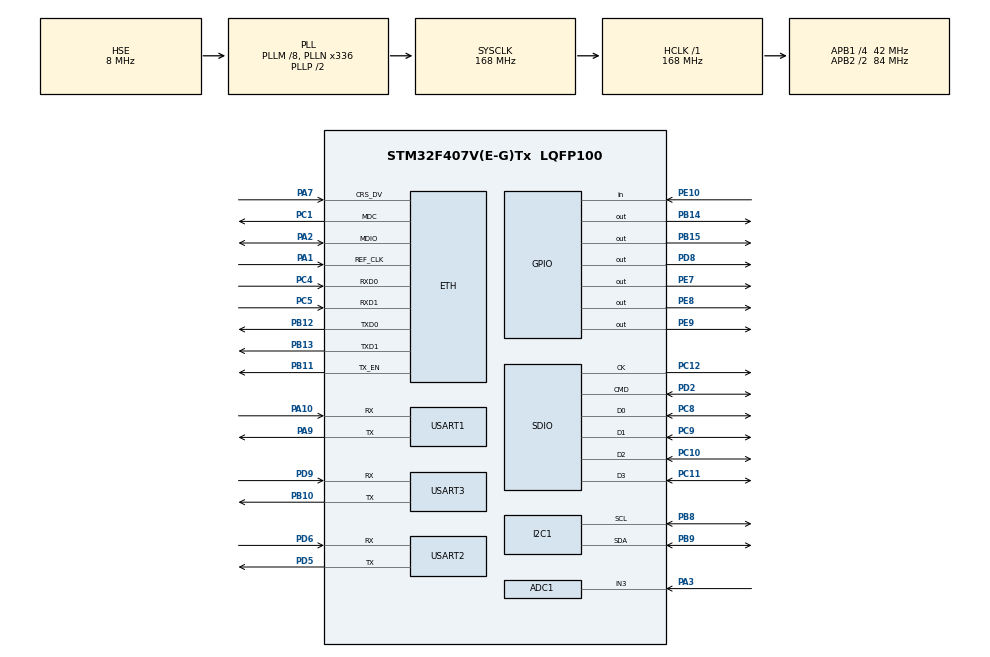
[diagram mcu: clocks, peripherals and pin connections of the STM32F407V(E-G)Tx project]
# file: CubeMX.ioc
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ADC1.Channel-0\#ChannelRegularConversion=ADC_CHANNEL_3
ADC1.NbrOfConversionFlag=1
ADC1.Rank-0\#ChannelRegularConversion=1
ADC1.SamplingTime-0\#ChannelRegularConversion=ADC_SAMPLETIME_3CYCLES
ADC1.master=1
ETH.MediaInterface=ETH_MEDIA_INTERFACE_RMII
FREERTOS.HEAP_NUMBER=3
FREERTOS.INCLUDE_eTaskGetState=0
FREERTOS.INCLUDE_pcTaskGetTaskName=1
FREERTOS.INCLUDE_vTaskDelayUntil=1
FREERTOS.INCLUDE_xQueueGetMutexHolder=0
FREERTOS.INCLUDE_xSemaphoreGetMutexHolder=0
FREERTOS.INCLUDE_xTaskGetCurrentTaskHandle=0
FREERTOS.Tasks01=defaultTask,0,128,StartDefaultTask,Default;keyboardTask,0,128,StartKeyboardTask,As external;ledIndicatorTask,0,128,StartLedIndicatorTask,As external;uartDebugTask,0,128,StartUartDebugTask,As external;HttpServerTask,0,128,StartHttpServerTask,As external;sdWorkerTask,0,128,StartSdWorkerTask,As external
FREERTOS.configCHECK_FOR_STACK_OVERFLOW=2
FREERTOS.configENABLE_BACKWARD_COMPATIBILITY=1
FREERTOS.configGENERATE_RUN_TIME_STATS=0
FREERTOS.configLIBRARY_LOWEST_INTERRUPT_PRIORITY=15
FREERTOS.configLIBRARY_MAX_SYSCALL_INTERRUPT_PRIORITY=5
FREERTOS.configMAX_PRIORITIES=16
FREERTOS.configMAX_TASK_NAME_LEN=24
FREERTOS.configTOTAL_HEAP_SIZE=15360
FREERTOS.configUSE_APPLICATION_TASK_TAG=0
FREERTOS.configUSE_COUNTING_SEMAPHORES=0
FREERTOS.configUSE_CO_ROUTINES=0
FREERTOS.configUSE_IDLE_HOOK=0
FREERTOS.configUSE_MALLOC_FAILED_HOOK=0
FREERTOS.configUSE_PORT_OPTIMISED_TASK_SELECTION=0
FREERTOS.configUSE_PREEMPTION=1
FREERTOS.configUSE_TICK_HOOK=0
FREERTOS.configUSE_TIMERS=0
LWIP.ARP_QUEUEING=0
LWIP.AUTOIP_DEBUG=LWIP_DBG_OFF
LWIP.CHECKSUM_BY_HARDWARE=0
LWIP.DEFAULT_THREAD_PRIO=7
LWIP.DHCP_DEBUG=LWIP_DBG_OFF
LWIP.DNS_DOES_NAME_CHECK=0
LWIP.ETHARP_SUPPORT_STATIC_ENTRIES=0
LWIP.ETHARP_SUPPORT_VLAN=0
LWIP.ETHARP_TABLE_MATCH_NETIF=0
LWIP.ETHARP_TRUST_IP_MAC=0
LWIP.GATEWAY_ADDRESS=192.168.001.001
LWIP.IP_ADDRESS=192.168.001.004
LWIP.IP_DEBUG=LWIP_DBG_OFF
LWIP.LWIP_DBG_TYPES_ON=LWIP_DBG_OFF
LWIP.LWIP_DHCP=1
LWIP.LWIP_DHCP_CHECK_LINK_UP=0
LWIP.LWIP_HAVE_SLIPIF=0
LWIP.LWIP_HTTPD=0
LWIP.LWIP_NETBUF_RECVINFO=1
LWIP.LWIP_NETCONN=1
LWIP.LWIP_NETCONN_SEM_PER_THREAD=0
LWIP.LWIP_NETIF_API=0
LWIP.LWIP_NETIF_HOSTNAME=0
LWIP.LWIP_NETIF_HWADDRHINT=0
LWIP.LWIP_NETIF_LINK_CALLBACK=0
LWIP.LWIP_NETIF_LOOPBACK=0
LWIP.LWIP_NETIF_REMOVE_CALLBACK=0
LWIP.LWIP_NETIF_STATUS_CALLBACK=0
LWIP.LWIP_SOCKET=1
LWIP.LWIP_SO_LINGER=0
LWIP.LWIP_SO_RCVBUF=0
LWIP.LWIP_STATS=0
LWIP.LWIP_TCP=1
LWIP.LWIP_TCPIP_TIMEOUT=0
LWIP.LWIP_TCP_TIMESTAMPS=1
LWIP.LWIP_UDP=1
LWIP.LWIP_UDPLITE=0
LWIP.MEMP_MEM_MALLOC=0
LWIP.MEM_LIBC_MALLOC=0
LWIP.NETIF_DEBUG=LWIP_DBG_OFF
LWIP.NETMASK_ADDRESS=255.255.255.000
LWIP.SOCKETS_DEBUG=LWIP_DBG_OFF
LWIP.SYS_LIGHTWEIGHT_PROT=0
LWIP.TCPIP_THREAD_PRIO=7
LWIP.UDP_DEBUG=LWIP_DBG_OFF
LWIP.Version=v1.5.0_RC0_20160211_Cube
Mcu.Family=STM32F4
Mcu.Name=STM32F407V(E-G)Tx
Mcu.Package=LQFP100
Mcu.UserConstants=configUSE_STATS_FORMATTING_FUNCTIONS,1
NVIC.ETH_IRQn=true\:5\:0\:true\:false\:true\:true
NVIC.PriorityGroup=NVIC_PRIORITYGROUP_4
PA1.Mode=RMII
PA1.Signal=ETH_REF_CLK
PA10.Mode=Asynchronous
PA10.Signal=USART1_RX
PA13.Mode=Serial_Wire
PA13.Signal=SYS_JTMS-SWDIO
PA14.Mode=Serial_Wire
PA14.Signal=SYS_JTCK-SWCLK
PA2.Mode=RMII
PA2.Signal=ETH_MDIO
PA3.Signal=ADCx_IN3
PA7.Mode=RMII
PA7.Signal=ETH_CRS_DV
PA9.Mode=Asynchronous
PA9.Signal=USART1_TX
PB10.Mode=Asynchronous
PB10.Signal=USART3_TX
PB11.Mode=RMII
PB11.Signal=ETH_TX_EN
PB12.Mode=RMII
PB12.Signal=ETH_TXD0
PB13.Mode=RMII
PB13.Signal=ETH_TXD1
PB14.Signal=GPIO_Output
PB15.Signal=GPIO_Output
PB8.Mode=I2C
PB8.Signal=I2C1_SCL
PB9.Mode=I2C
PB9.Signal=I2C1_SDA
PC1.Mode=RMII
PC1.Signal=ETH_MDC
PC10.Mode=SD_4_bits_Wide_bus
PC10.Signal=SDIO_D2
PC11.Mode=SD_4_bits_Wide_bus
PC11.Signal=SDIO_D3
PC12.Mode=SD_4_bits_Wide_bus
PC12.Signal=SDIO_CK
PC14-OSC32_IN.Mode=LSE-External-Oscillator
PC14-OSC32_IN.Signal=RCC_OSC32_IN
PC15-OSC32_OUT.Mode=LSE-External-Oscillator
PC15-OSC32_OUT.Signal=RCC_OSC32_OUT
PC4.Mode=RMII
PC4.Signal=ETH_RXD0
PC5.Mode=RMII
PC5.Signal=ETH_RXD1
PC8.Mode=SD_4_bits_Wide_bus
PC8.Signal=SDIO_D0
PC9.Mode=SD_4_bits_Wide_bus
PC9.Signal=SDIO_D1
PD2.Mode=SD_4_bits_Wide_bus
PD2.Signal=SDIO_CMD
PD5.Mode=Asynchronous
PD5.Signal=USART2_TX
PD6.Mode=Asynchronous
PD6.Signal=USART2_RX
PD8.Signal=GPIO_Output
PD9.Mode=Asynchronous
PD9.Signal=USART3_RX
PE10.Signal=GPIO_Input
PE7.Signal=GPIO_Output
PE8.Signal=GPIO_Output
PE9.Signal=GPIO_Output
PH0-OSC_IN.Mode=HSE-External-Oscillator
PH0-OSC_IN.Signal=RCC_OSC_IN
PH1-OSC_OUT.Mode=HSE-External-Oscillator
PH1-OSC_OUT.Signal=RCC_OSC_OUT
ProjectManager.HeapSize=0x200
ProjectManager.StackSize=0x400
ProjectManager.TargetToolchain=TrueSTUDIO
RCC.48MHZClocksFreq_Value=48000000
RCC.AHBFreq_Value=168000000
RCC.APB1CLKDivider=RCC_HCLK_DIV4
RCC.APB1Freq_Value=42000000
RCC.APB1TimFreq_Value=84000000
RCC.APB2CLKDivider=RCC_HCLK_DIV2
RCC.APB2Freq_Value=84000000
RCC.APB2TimFreq_Value=168000000
RCC.CortexFreq_Value=168000000
RCC.HCLKFreq_Value=168000000
RCC.HSE_VALUE=8000000
RCC.HSI_VALUE=16000000
RCC.PLLM=8
RCC.PLLN=336
RCC.PLLQ=7
RCC.PLLSourceVirtual=RCC_PLLSOURCE_HSE
RCC.SYSCLKFreq_VALUE=168000000
RCC.SYSCLKSource=RCC_SYSCLKSOURCE_PLLCLK
RCC.VCOOutputFreq_Value=336000000
SDIO.BusWide=SDIO_BUS_WIDE_1B
SDIO.WideMode=SDIO_BUS_WIDE_4B
SH.ADCx_IN3.0=ADC1_IN3,IN3
VP_ADC1_TempSens_Input.Mode=IN-TempSens
VP_ADC1_Vbat_Input.Mode=IN-Vbat
VP_ADC1_Vref_Input.Mode=IN-Vrefint
VP_FATFS_VS_Generic.Mode=User_defined
VP_FATFS_VS_SDIO.Mode=SDIO
VP_FREERTOS_VS_ENABLE.Mode=Enabled
VP_LWIP_VS_Enabled.Mode=Enabled
VP_TIM6_VS_ClockSourceINT.Mode=Enable_Timer
board=CubeMX

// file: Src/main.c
/**
  ******************************************************************************
  * File Name          : main.c
  * Description        : Main program body
  ******************************************************************************
  *
  * COPYRIGHT(c) 2016 STMicroelectronics
  *
  * Redistribution and use in source and binary forms, with or without modification,
  * are permitted provided that the following conditions are met:
  *   1. Redistributions of source code must retain the above copyright notice,
  *      this list of conditions and the following disclaimer.
  *   2. Redistributions in binary form must reproduce the above copyright notice,
  *      this list of conditions and the following disclaimer in the documentation
  *      and/or other materials provided with the distribution.
  *   3. Neither the name of STMicroelectronics nor the names of its contributors
  *      may be used to endorse or promote products derived from this software
  *      without specific prior written permission.
  *
  * THIS SOFTWARE IS PROVIDED BY THE COPYRIGHT HOLDERS AND CONTRIBUTORS "AS IS"
  * AND ANY EXPRESS OR IMPLIED WARRANTIES, INCLUDING, BUT NOT LIMITED TO, THE
  * IMPLIED WARRANTIES OF MERCHANTABILITY AND FITNESS FOR A PARTICULAR PURPOSE ARE
  * DISCLAIMED. IN NO EVENT SHALL THE COPYRIGHT HOLDER OR CONTRIBUTORS BE LIABLE
  * FOR ANY DIRECT, INDIRECT, INCIDENTAL, SPECIAL, EXEMPLARY, OR CONSEQUENTIAL
  * DAMAGES (INCLUDING, BUT NOT LIMITED TO, PROCUREMENT OF SUBSTITUTE GOODS OR
  * SERVICES; LOSS OF USE, DATA, OR PROFITS; OR BUSINESS INTERRUPTION) HOWEVER
  * CAUSED AND ON ANY THEORY OF LIABILITY, WHETHER IN CONTRACT, STRICT LIABILITY,
  * OR TORT (INCLUDING NEGLIGENCE OR OTHERWISE) ARISING IN ANY WAY OUT OF THE USE
  * OF THIS SOFTWARE, EVEN IF ADVISED OF THE POSSIBILITY OF SUCH DAMAGE.
  *
  ******************************************************************************
  */
#include "stm32f4xx_hal.h"
#include "cmsis_os.h"
#include "adc.h"
#include "fatfs.h"
#include "i2c.h"
#include "lwip.h"
#include "sdio.h"
#include "tim.h"
#include "usart.h"
#include "gpio.h"

/* USER CODE BEGIN PV */
/* Private variables ---------------------------------------------------------*/

/* USER CODE END PV */

void SystemClock_Config(void);
void Error_Handler(void);
void MX_FREERTOS_Init(void);

/* USER CODE BEGIN PFP */
/* Private function prototypes -----------------------------------------------*/

/* USER CODE END PFP */

int main(void)
{

  /* MCU Configuration----------------------------------------------------------*/

  /* Reset of all peripherals, Initializes the Flash interface and the Systick. */
  HAL_Init();

  /* Configure the system clock */
  SystemClock_Config();

  /* Initialize all configured peripherals */
  MX_GPIO_Init();
  MX_ADC1_Init();
  MX_I2C1_Init();
  MX_SDIO_SD_Init();
  MX_TIM6_Init();
  MX_USART3_UART_Init();
  MX_USART2_UART_Init();
  MX_USART1_UART_Init();

  /* Call init function for freertos objects (in freertos.c) */
  MX_FREERTOS_Init();

  /* Start scheduler */
  osKernelStart();

  /* We should never get here as control is now taken by the scheduler */

  /* Infinite loop */
  while (1)
  {

  }

}

/** System Clock Configuration
*/
void SystemClock_Config(void)
{

  RCC_OscInitTypeDef RCC_OscInitStruct;
  RCC_ClkInitTypeDef RCC_ClkInitStruct;

  __HAL_RCC_PWR_CLK_ENABLE();

  __HAL_PWR_VOLTAGESCALING_CONFIG(PWR_REGULATOR_VOLTAGE_SCALE1);

  RCC_OscInitStruct.OscillatorType = RCC_OSCILLATORTYPE_HSE;
  RCC_OscInitStruct.HSEState = RCC_HSE_ON;
  RCC_OscInitStruct.PLL.PLLState = RCC_PLL_ON;
  RCC_OscInitStruct.PLL.PLLSource = RCC_PLLSOURCE_HSE;
  RCC_OscInitStruct.PLL.PLLM = 8;
  RCC_OscInitStruct.PLL.PLLN = 336;
  RCC_OscInitStruct.PLL.PLLP = RCC_PLLP_DIV2;
  RCC_OscInitStruct.PLL.PLLQ = 7;
  if (HAL_RCC_OscConfig(&RCC_OscInitStruct) != HAL_OK)
  {
    Error_Handler();
  }

  RCC_ClkInitStruct.ClockType = RCC_CLOCKTYPE_HCLK|RCC_CLOCKTYPE_SYSCLK
                              |RCC_CLOCKTYPE_PCLK1|RCC_CLOCKTYPE_PCLK2;
  RCC_ClkInitStruct.SYSCLKSource = RCC_SYSCLKSOURCE_PLLCLK;
  RCC_ClkInitStruct.AHBCLKDivider = RCC_SYSCLK_DIV1;
  RCC_ClkInitStruct.APB1CLKDivider = RCC_HCLK_DIV4;
  RCC_ClkInitStruct.APB2CLKDivider = RCC_HCLK_DIV2;
  if (HAL_RCC_ClockConfig(&RCC_ClkInitStruct, FLASH_LATENCY_5) != HAL_OK)
  {
    Error_Handler();
  }

  HAL_SYSTICK_Config(HAL_RCC_GetHCLKFreq()/1000);

  HAL_SYSTICK_CLKSourceConfig(SYSTICK_CLKSOURCE_HCLK);

  /* SysTick_IRQn interrupt configuration */
  HAL_NVIC_SetPriority(SysTick_IRQn, 15, 0);
}

void Error_Handler(void)
{
  while(1)
  {
  }
}

/************************ (C) COPYRIGHT STMicroelectronics *****END OF FILE****/

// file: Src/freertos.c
/**
  ******************************************************************************
  * File Name          : freertos.c
  * Description        : Code for freertos applications
  ******************************************************************************
  *
  * COPYRIGHT(c) 2016 STMicroelectronics
  *
  * Redistribution and use in source and binary forms, with or without modification,
  * are permitted provided that the following conditions are met:
  *   1. Redistributions of source code must retain the above copyright notice,
  *      this list of conditions and the following disclaimer.
  *   2. Redistributions in binary form must reproduce the above copyright notice,
  *      this list of conditions and the following disclaimer in the documentation
  *      and/or other materials provided with the distribution.
  *   3. Neither the name of STMicroelectronics nor the names of its contributors
  *      may be used to endorse or promote products derived from this software
  *      without specific prior written permission.
  *
  * THIS SOFTWARE IS PROVIDED BY THE COPYRIGHT HOLDERS AND CONTRIBUTORS "AS IS"
  * AND ANY EXPRESS OR IMPLIED WARRANTIES, INCLUDING, BUT NOT LIMITED TO, THE
  * IMPLIED WARRANTIES OF MERCHANTABILITY AND FITNESS FOR A PARTICULAR PURPOSE ARE
  * DISCLAIMED. IN NO EVENT SHALL THE COPYRIGHT HOLDER OR CONTRIBUTORS BE LIABLE
  * FOR ANY DIRECT, INDIRECT, INCIDENTAL, SPECIAL, EXEMPLARY, OR CONSEQUENTIAL
  * DAMAGES (INCLUDING, BUT NOT LIMITED TO, PROCUREMENT OF SUBSTITUTE GOODS OR
  * SERVICES; LOSS OF USE, DATA, OR PROFITS; OR BUSINESS INTERRUPTION) HOWEVER
  * CAUSED AND ON ANY THEORY OF LIABILITY, WHETHER IN CONTRACT, STRICT LIABILITY,
  * OR TORT (INCLUDING NEGLIGENCE OR OTHERWISE) ARISING IN ANY WAY OUT OF THE USE
  * OF THIS SOFTWARE, EVEN IF ADVISED OF THE POSSIBILITY OF SUCH DAMAGE.
  *
  ******************************************************************************
  */

#include "FreeRTOS.h"
#include "task.h"
#include "cmsis_os.h"

/* USER CODE BEGIN Includes */
#include "stm32f4xx_hal.h"
/* USER CODE END Includes */

osThreadId defaultTaskHandle;
osThreadId keyboardTaskHandle;
osThreadId ledIndicatorTaskHandle;
osThreadId uartDebugTaskHandle;
osThreadId HttpServerTaskHandle;
osThreadId sdWorkerTaskHandle;

void StartDefaultTask(void const * argument);
extern void StartKeyboardTask(void const * argument);
extern void StartLedIndicatorTask(void const * argument);
extern void StartUartDebugTask(void const * argument);
extern void StartHttpServerTask(void const * argument);
extern void StartSdWorkerTask(void const * argument);

extern void MX_FATFS_Init(void);
extern void MX_LWIP_Init(void);
void MX_FREERTOS_Init(void); /* (MISRA C 2004 rule 8.1) */

/* Hook prototypes */
void vApplicationStackOverflowHook(xTaskHandle xTask, signed char *pcTaskName);

/* USER CODE BEGIN 4 */
void vApplicationStackOverflowHook(xTaskHandle xTask, signed char *pcTaskName)
{
   /* Run time stack overflow checking is performed if
   configCHECK_FOR_STACK_OVERFLOW is defined to 1 or 2. This hook function is
   called if a stack overflow is detected. */
}
/* USER CODE END 4 */

/* Init FreeRTOS */

void MX_FREERTOS_Init(void) {

  /* Create the thread(s) */
  /* definition and creation of defaultTask */
  osThreadDef(defaultTask, StartDefaultTask, osPriorityNormal, 0, 128);
  defaultTaskHandle = osThreadCreate(osThread(defaultTask), NULL);

  /* definition and creation of keyboardTask */
  osThreadDef(keyboardTask, StartKeyboardTask, osPriorityNormal, 0, 128);
  keyboardTaskHandle = osThreadCreate(osThread(keyboardTask), NULL);

  /* definition and creation of ledIndicatorTask */
  osThreadDef(ledIndicatorTask, StartLedIndicatorTask, osPriorityNormal, 0, 128);
  ledIndicatorTaskHandle = osThreadCreate(osThread(ledIndicatorTask), NULL);

  /* definition and creation of uartDebugTask */
  osThreadDef(uartDebugTask, StartUartDebugTask, osPriorityNormal, 0, 128);
  uartDebugTaskHandle = osThreadCreate(osThread(uartDebugTask), NULL);

  /* definition and creation of HttpServerTask */
  osThreadDef(HttpServerTask, StartHttpServerTask, osPriorityNormal, 0, 128);
  HttpServerTaskHandle = osThreadCreate(osThread(HttpServerTask), NULL);

  /* definition and creation of sdWorkerTask */
  osThreadDef(sdWorkerTask, StartSdWorkerTask, osPriorityNormal, 0, 128);
  sdWorkerTaskHandle = osThreadCreate(osThread(sdWorkerTask), NULL);

}

/* StartDefaultTask function */
void StartDefaultTask(void const * argument)
{
  /* init code for FATFS */
  MX_FATFS_Init();

  /* init code for LWIP */
  MX_LWIP_Init();

  /* USER CODE BEGIN StartDefaultTask */
  /* Infinite loop */
  for(;;)
  {
    HAL_GPIO_TogglePin(GPIOB, GPIO_PIN_15);
    osDelay(200);
  }
  /* USER CODE END StartDefaultTask */
}

/************************ (C) COPYRIGHT STMicroelectronics *****END OF FILE****/
